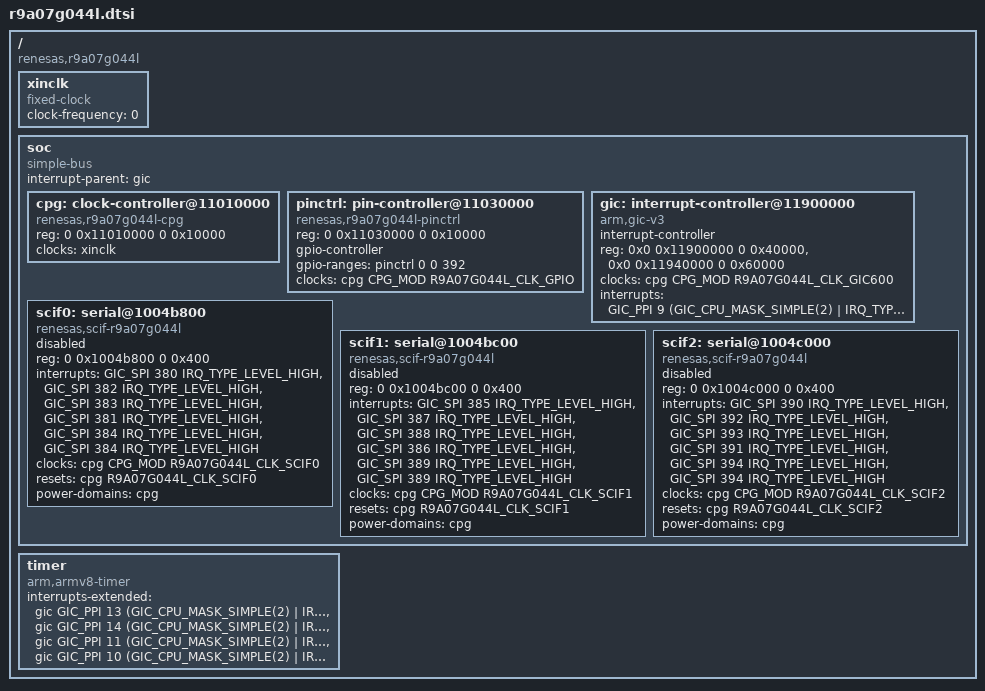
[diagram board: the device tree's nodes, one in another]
// SPDX-License-Identifier: GPL-2.0
/*
 * Device Tree Source for the RZ/G2L series (R9A07G044Lx) SoC
 *
 * Copyright (C) 2021 Renesas Electronics Corp.
 */

#include <dt-bindings/interrupt-controller/arm-gic.h>
#include <dt-bindings/clock/r9a07g044l-cpg.h>

/ {
	compatible = "renesas,r9a07g044l";
	#address-cells = <2>;
	#size-cells = <2>;

	xinclk: xinclk {
		compatible = "fixed-clock";
		#clock-cells = <0>;
		/* This value must be overridden by the board */
		clock-frequency = <0>;
	};

	soc: soc {
		compatible = "simple-bus";
		interrupt-parent = <&gic>;
		#address-cells = <2>;
		#size-cells = <2>;
		ranges;

		cpg: clock-controller@11010000 {
			compatible = "renesas,r9a07g044l-cpg";
			reg = <0 0x11010000 0 0x10000>;
			clocks = <&xinclk>;
			clock-names = "xinclk";
			#clock-cells = <2>;
			#reset-cells = <1>;
			#power-domain-cells = <0>;
		};

		pinctrl: pin-controller@11030000 {
			compatible = "renesas,r9a07g044l-pinctrl";
			reg = <0 0x11030000 0 0x10000>;
			gpio-controller;
			#gpio-cells = <2>;
			gpio-ranges = <&pinctrl 0 0 392>;
			clocks = <&cpg CPG_MOD R9A07G044L_CLK_GPIO>;
		};

		gic: interrupt-controller@11900000 {
			compatible = "arm,gic-v3";
			#interrupt-cells = <3>;
			#address-cells = <0>;
			interrupt-controller;
			reg = <0x0 0x11900000 0 0x40000>,
			      <0x0 0x11940000 0 0x60000>;
			clocks = <&cpg CPG_MOD R9A07G044L_CLK_GIC600>;
			clock-names = "gic6000";
			interrupts = <GIC_PPI 9
				(GIC_CPU_MASK_SIMPLE(2) | IRQ_TYPE_LEVEL_LOW)>;
		};

		scif0: serial@1004b800 {
			compatible = "renesas,scif-r9a07g044l";
			reg = <0 0x1004b800 0 0x400>;
			interrupts =
				<GIC_SPI 380 IRQ_TYPE_LEVEL_HIGH>,
				<GIC_SPI 382 IRQ_TYPE_LEVEL_HIGH>,
				<GIC_SPI 383 IRQ_TYPE_LEVEL_HIGH>,
				<GIC_SPI 381 IRQ_TYPE_LEVEL_HIGH>,
				<GIC_SPI 384 IRQ_TYPE_LEVEL_HIGH>,
				<GIC_SPI 384 IRQ_TYPE_LEVEL_HIGH>;
			clocks = <&cpg CPG_MOD R9A07G044L_CLK_SCIF0>;
			clock-names = "fck";
			resets = <&cpg R9A07G044L_CLK_SCIF0>;
			power-domains = <&cpg>;
			status = "disable";
		};

		scif1: serial@1004bc00 {
			compatible = "renesas,scif-r9a07g044l";
			reg = <0 0x1004bc00 0 0x400>;
			interrupts =
				<GIC_SPI 385 IRQ_TYPE_LEVEL_HIGH>,
				<GIC_SPI 387 IRQ_TYPE_LEVEL_HIGH>,
				<GIC_SPI 388 IRQ_TYPE_LEVEL_HIGH>,
				<GIC_SPI 386 IRQ_TYPE_LEVEL_HIGH>,
				<GIC_SPI 389 IRQ_TYPE_LEVEL_HIGH>,
				<GIC_SPI 389 IRQ_TYPE_LEVEL_HIGH>;
			clocks = <&cpg CPG_MOD R9A07G044L_CLK_SCIF1>;
			clock-names = "fck";
			resets = <&cpg R9A07G044L_CLK_SCIF1>;
			power-domains = <&cpg>;
			status = "disable";
		};

		scif2: serial@1004c000 {
			compatible = "renesas,scif-r9a07g044l";
			reg = <0 0x1004c000 0 0x400>;
			interrupts =
				<GIC_SPI 390 IRQ_TYPE_LEVEL_HIGH>,
				<GIC_SPI 392 IRQ_TYPE_LEVEL_HIGH>,
				<GIC_SPI 393 IRQ_TYPE_LEVEL_HIGH>,
				<GIC_SPI 391 IRQ_TYPE_LEVEL_HIGH>,
				<GIC_SPI 394 IRQ_TYPE_LEVEL_HIGH>,
				<GIC_SPI 394 IRQ_TYPE_LEVEL_HIGH>;
			clocks = <&cpg CPG_MOD R9A07G044L_CLK_SCIF2>;
			clock-names = "fck";
			resets = <&cpg R9A07G044L_CLK_SCIF2>;
			power-domains = <&cpg>;
			status = "disable";
		};
	};

	timer {
		compatible = "arm,armv8-timer";
		interrupts-extended =
		<&gic GIC_PPI 13
			(GIC_CPU_MASK_SIMPLE(2) | IRQ_TYPE_LEVEL_LOW)>,
		<&gic GIC_PPI 14
			(GIC_CPU_MASK_SIMPLE(2) | IRQ_TYPE_LEVEL_LOW)>,
		<&gic GIC_PPI 11
			(GIC_CPU_MASK_SIMPLE(2) | IRQ_TYPE_LEVEL_LOW)>,
		<&gic GIC_PPI 10
			(GIC_CPU_MASK_SIMPLE(2) | IRQ_TYPE_LEVEL_LOW)>;
	};
};

